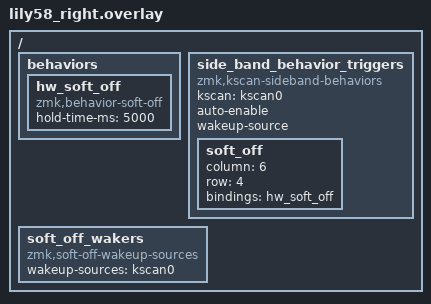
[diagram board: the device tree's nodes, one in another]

/ {
	behaviors {
		hw_soft_off: hw_soft_off {
			compatible = "zmk,behavior-soft-off";
            #binding-cells = <0>;
            hold-time-ms = <5000>;
		};
	};

    side_band_behavior_triggers: side_band_behavior_triggers {
        compatible = "zmk,kscan-sideband-behaviors";

        kscan = <&kscan0>;
        auto-enable;
        wakeup-source;

        soft_off {
            column = <6>;
            row = <4>;
            bindings = <&hw_soft_off>;
        };
    };

    soft_off_wakers {
        compatible = "zmk,soft-off-wakeup-sources";
        wakeup-sources = <&kscan0>;
    };
};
